# nrf7120E_enga_application register map
Vendor: Nordic Semiconductor; Series: nrf71; File version: 1
CPU: CM33 r0p4, little endian, MPU, FPU, 3 interrupt priority bits, 270 interrupts, 4 SAU regions
Registers are 32-bit, read-write, reset 0x0 unless marked. A register's access mark holds for its fields unless they carry their own. Offsets are from the block's base; [hi:lo] are bit positions; lines under a group give offsets from that group; 'fields as' and 'values as' point back to an identical list.

## GLOBAL_RESET_NS — Reset control 0
Base 0x4010E000; alternate view of GLOBAL_CLOCK_NS
Same registers: GLOBAL_RESET_S 0x5010E000 (alternate view of GLOBAL_CLOCK_S)
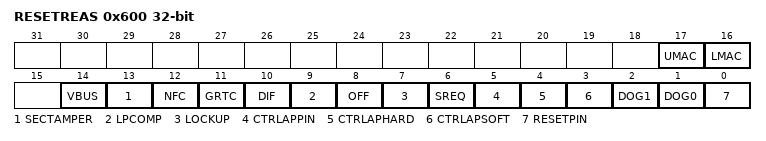
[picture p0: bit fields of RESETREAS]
0x600 RESETREAS — Reset reason
  [all] fields
    0=NotDetected; 1=Detected
  [17] UMAC — Reset from Wi-Fi UMAC watchdog
  [16] LMAC — Reset from Wi-Fi LMAC watchdog
  [14] VBUS — Reset after wake-up from System OFF mode due to VBUS rising into valid range
  [13] SECTAMPER — Reset due to illegal tampering of the device
  [12] NFC — Reset after wake-up from System OFF mode due to NFC field being detected
  [11] GRTC — Reset due to wake-up from GRTC
  [10] DIF — Reset triggered by Debug Interface
  [9] LPCOMP — Reset due to wake-up from System OFF mode when wake-up is triggered by ANADETECT signal from LPCOMP
  [8] OFF — Reset due to wake-up from System OFF mode when wake-up is triggered by DETECT signal from GPIO
  [7] LOCKUP — Reset from CPU lockup detected
  [6] SREQ — Reset from soft reset detected
  [5] CTRLAPPIN — Reset due to CTRL-AP pin reset
  [4] CTRLAPHARD — Reset due to CTRL-AP hard reset
  [3] CTRLAPSOFT — Soft reset from CTRL-AP detected
  [2] DOG1 — Reset from watchdog timer 1 detected
  [1] DOG0 — Reset from watchdog timer 0 detected
  [0] RESETPIN — Reset from pin reset detected

## GLOBAL_GLITCHDET_S — Voltage glitch detectors
Base 0x50111000
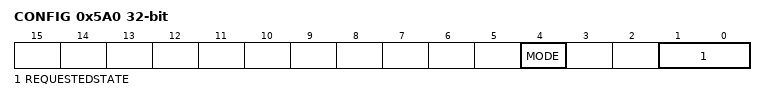
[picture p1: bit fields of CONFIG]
0x5A0 CONFIG — Configuration for glitch detector
  [4] MODE — Glitch detector mode
    0=High pass filter mode; 1=Cap divider mode
  [1:0] REQUESTEDSTATE — Requested state of the glitch detector.
    0=Disabled: Glitch detector shall be disabled; 1=Enabled: Glitch detector shall be enabled; 2=Keep: Do not change the state of glitch detector, keep it as it is

## GLOBAL_OSCILLATORS_NS — Oscillator control 0
Base 0x40120000
Same registers: GLOBAL_OSCILLATORS_S 0x50120000
0x800 PLL group — Oscillator control
  0x00 FREQ reset 0x4 — Set speed of MCU power domain, including CPU.
    [2:0] FREQ — Select CPU speed
      0=CK256M (256 MHz); 1=CK192M (192 MHz); 2=CK128M (128 MHz); 3=CK96M (96 MHz); 4=CK64M (64 MHz)
  0x04 CURRENTFREQ ro reset 0x4 — Current speed of MCU power domain, including CPU
    [2:0] CURRENTFREQ — Select CPU speed
      values as PLL.FREQ.FREQ

## GLOBAL_REGULATORS_NS — Voltage regulators 0
Base 0x40120000; alternate view of GLOBAL_OSCILLATORS_NS
Same registers: GLOBAL_REGULATORS_S 0x50120000 (alternate view of GLOBAL_OSCILLATORS_S)
0x500 SYSTEMOFF wo
  [0] SYSTEMOFF — Enable System OFF mode
    1=Enter (Enable System OFF mode)
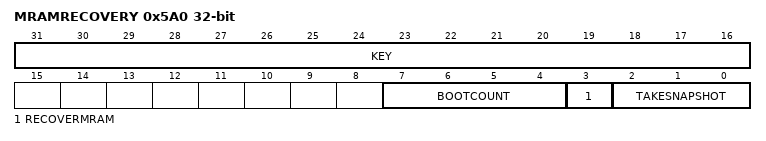
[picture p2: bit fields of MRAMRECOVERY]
0x5A0 MRAMRECOVERY — MRAM snapshot and recovery trigger register
  [31:16] KEY wo — Write key. KEY must be written to 0xB7A6 when writing MRAMRECOVERY register.
    0xB7A6=Key (Write key value.)
  [7:4] BOOTCOUNT — Boot counter for MRAM recovery triggering in the presence of a boot loop. Firmware must clear this to zero on a successful boot.
  [3] RECOVERMRAM — Firmware sets this bit to request ROM to recover from snapshot during the next boot.
  [2:0] TAKESNAPSHOT — Firmware sets this bit to request ROM to take an MRAM snapshot during the next boot.
    0=Do nothing (default); 1=takesnapshot (Trigger snapshot generation on the next boot.); 2=success (Indicates successful snapshot generation on previous boot.); 6=nomoresnapshots (Error during snapshot generation - there is no remaining space in FUSE array to secure another snapshot.); 7=error (Unspecified error during snapshot generation.)

## GLOBAL_VREGUSB_NS — VREGUSB peripheral 0
Base 0x40121000
Same registers: GLOBAL_VREGUSB_S 0x50121000
0x00 TASKS_START wo — Enable and start VREGUSB so that it can detect VBUS
  [0] TASKS_START
    1=Trigger task
0x04 TASKS_STOP wo — Stop and disable VREGUSB
  [0] TASKS_STOP
    1=Trigger task
0x104 EVENTS_VBUSDETECTED — VBUS detected
  [0] EVENTS_VBUSDETECTED
    0=NotGenerated (Event not generated); 1=Generated (Event generated)
0x10C EVENTS_SETTLED3V3 — 3V3 settled
  [0] EVENTS_SETTLED3V3
    values as EVENTS_VBUSDETECTED.EVENTS_VBUSDETECTED
0x110 EVENTS_VBUSREMOVED — VBUS removed
  [0] EVENTS_VBUSREMOVED
    values as EVENTS_VBUSDETECTED.EVENTS_VBUSDETECTED
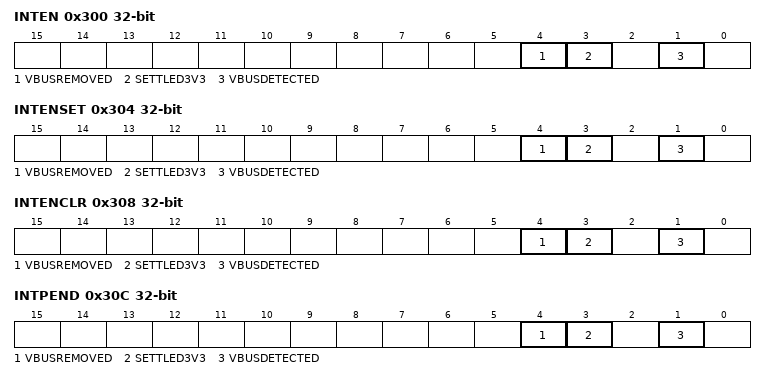
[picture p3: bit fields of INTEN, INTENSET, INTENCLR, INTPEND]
0x300 INTEN — Enable or disable interrupt
  [all] fields
    0=Disabled; 1=Enabled
  [4] VBUSREMOVED — Enable or disable interrupt for event VBUSREMOVED
  [3] SETTLED3V3 — Enable or disable interrupt for event SETTLED3V3
  [1] VBUSDETECTED — Enable or disable interrupt for event VBUSDETECTED
0x304 INTENSET — Enable interrupt
  [all] fields
    on read: 0=Disabled (Read: Disabled); 1=Enabled (Read: Enabled) | on write: 1=Set (Enable)
  [4] VBUSREMOVED write-1-sets — Write '1' to enable interrupt for event VBUSREMOVED
  [3] SETTLED3V3 write-1-sets — Write '1' to enable interrupt for event SETTLED3V3
  [1] VBUSDETECTED write-1-sets — Write '1' to enable interrupt for event VBUSDETECTED
0x308 INTENCLR — Disable interrupt
  [all] fields
    on read: 0=Disabled (Read: Disabled); 1=Enabled (Read: Enabled) | on write: 1=Clear (Disable)
  [4] VBUSREMOVED write-1-clears — Write '1' to disable interrupt for event VBUSREMOVED
  [3] SETTLED3V3 write-1-clears — Write '1' to disable interrupt for event SETTLED3V3
  [1] VBUSDETECTED write-1-clears — Write '1' to disable interrupt for event VBUSDETECTED
0x30C INTPEND ro — Pending interrupts
  [all] fields
    on read: 0=NotPending (Read: Not pending); 1=Pending (Read: Pending)
  [4] VBUSREMOVED — Read pending status of interrupt for event VBUSREMOVED
  [3] SETTLED3V3 — Read pending status of interrupt for event SETTLED3V3
  [1] VBUSDETECTED — Read pending status of interrupt for event VBUSDETECTED
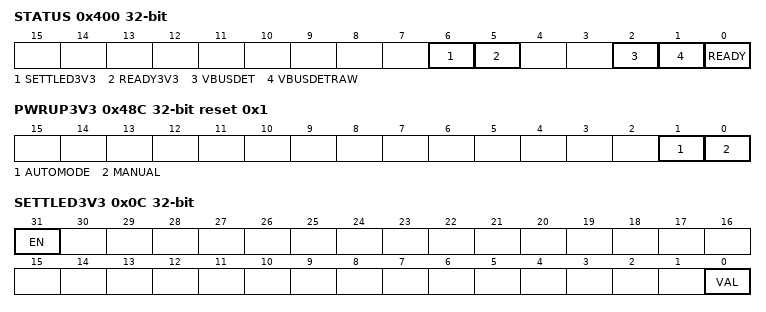
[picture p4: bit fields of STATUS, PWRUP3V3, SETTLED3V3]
0x400 STATUS ro — Status of USB PM
  [6] SETTLED3V3 — Power 3V3 settled
    0=NotSettled3v3 (Power 3V3 not settled); 1=Settled3v3 (Power 3V3 settled)
  [5] READY3V3 — Power 3V3 ready
    0=NotReady3v3 (Power 3V3 not ready); 1=Ready3v3 (Power 3V3 ready)
  [2] VBUSDET — VBUS detected, filtered
    0=NotVbusDet (VBUS not detected); 1=VBUS detected
  [1] VBUSDETRAW — VBUS detected, raw signal
    0=NotVbusDetRaw (VBUS not detected); 1=VbusDetRaw (VBUS detected)
  [0] READY — USB PM ready
    0=PowerDown (USB PM powered down); 1=Powered (USB PM powered up)
0x410 CONFIG group — Unspecified
  0x10 SETL3V3TIM reset 0x1F40 — Time from LDO ready to SETTLED3V3 (0us-1000us)
    [13:0] VAL — Timer value
      0=Min (0 us); 0x1F40=Default (500 us); 0x3E80=Max (1000 us)
0x48C PWRUP3V3 reset 0x1 — Power up 3V3
  [1] AUTOMODE — Automatic power mode configuration
    0=Auto (USB 3V3 regulator automatically powered); 1=Manual (USB 3V3 regulator manually powered)
  [0] MANUAL — Manual power mode configuration for 3V3 regulator
    0=Off (USB 3V3 regulator powered down in manual mode); 1=On (USB 3V3 regulator powered up in manual mode)
0x500 OVERRIDE group — Unspecified
  0x0C SETTLED3V3 — Override the SETTLED3V3 from the digital part
    [31] EN — Enable the override
      0=Disabled (Override is disabled); 1=Enabled (Override is enabled)
    [0] VAL — Override value for the signal
